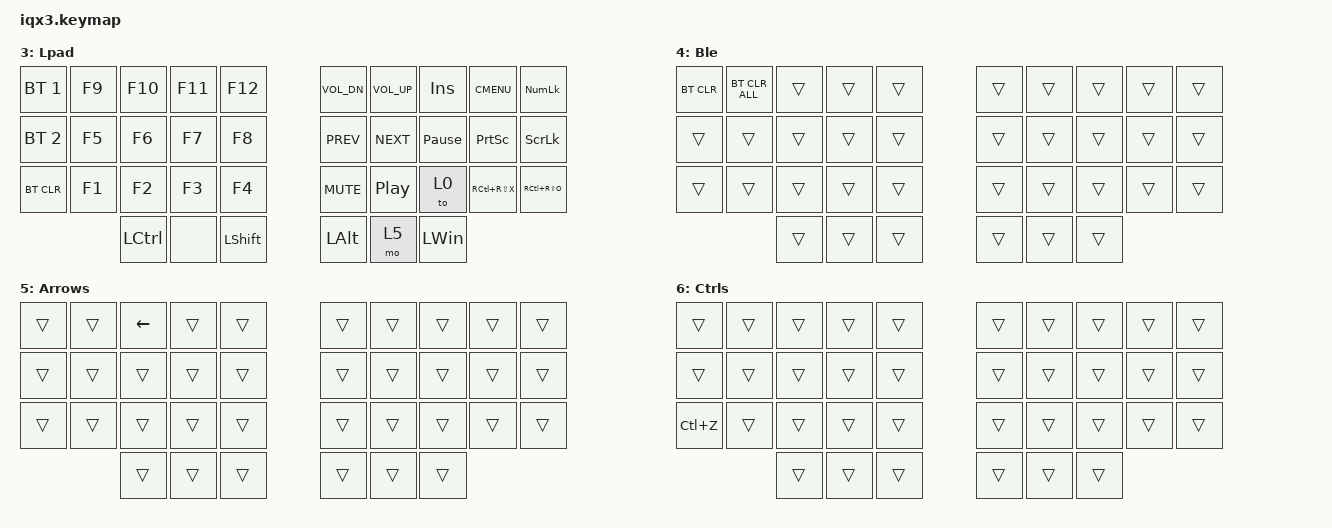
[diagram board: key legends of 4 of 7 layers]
/*
 * Copyright (c) 2020 The ZMK Contributors
 *
 * SPDX-License-Identifier: MIT
 */

#include <behaviors.dtsi>
#include <dt-bindings/zmk/bt.h>
#include <dt-bindings/zmk/keys.h>

/ {
    keymap0: keymap {
        compatible = "zmk,keymap";

        Base {
            // &mt LCTRL ESC  &lt 1 SPACE  &kp LSHFT  &mt LALT TAB  &lt 2 SPACE  &mt LWIN DEL

            // | --- |   Q   |   W   |   E   |   R   |   T   |   Y   |   U   |   I   |   O   |   P   |  --- |
            // | --- |   A   |   S   |   D   |   F   |   G   |   H   |   J   |   K   |   L   |  Ent  |  --- |
            // | --- |   Z   |   X   |   C   |   V   |   B   |   N   |   M   | 3,Spc |  Del  |  BS   |  --- |
            // | --- |  ---  |  ---  | LCtrl | MO(1) | LSht  |  LAlt | MO(2) | LWin  |  ---  |  ---  |  --- | 
            bindings = <
&none    &lt 1 Q     &kp W     &kp E         &kp R       &kp T     &kp Y        &kp U       &kp I          &kp O       &kp P     &none
&none    &lt 2 A     &kp S     &kp D         &kp F       &kp G     &kp H        &kp J       &kp K          &kp L       &kp ENTER &none 
&none    &lt 3 Z     &kp X     &kp C         &kp V       &kp B     &kp N        &kp M       &kp COMMA    &kp DOT   &kp BSPC  &none
&none    &none     &none     &kp ESC       &kp TAB     &kp CAPS  &kp LSHFT    &kp LCTRL   &kp SPACE   &none       &none     &none        
            >;
        };

        Number {
            // | ---| a 1 2 3 + - * / = bspc --- |
            // | --- 0 4 5 6 ! @ # $ % ^--- |
            // | --- . 7 8 9 & * () _ |  --- |
            // | --- 
            // | --- |   7   |   8   |   9   |   .   |   +   |   *   |   $   |   :   |   |   |   `   |  --- |
            // | --- |   4   |   5   |   6   |   0   |   -   |   /   |   #   |   {   |   }   |   ;   |  --- |
            // | --- |   1   |   2   |   3   |  BS   | P-Ent |  CAPS | #Spc  |   ,   |   .   | !#BS  |  --- |
            // | --- |  ---  |  ---  | LCtrl | TO(0) | LSht  |  LAlt | #Spc  | LWin  |  ---  |  ---  |  --- | 
            bindings = <
 &none   &kp N7    &kp N8    &kp N9    &kp KP_DOT &kp KP_PLUS         &kp KP_MULTIPLY  &kp DLLR      &kp COLON  &kp PIPE   &kp GRAVE    &none 
 &none   &kp N4    &kp N5    &kp N6    &kp N0     &kp KP_MINUS        &kp KP_SLASH     &kp HASH      &kp LBRC   &kp RBRC   &kp SEMI     &none  
 &none   &kp N1    &kp N2    &kp N3    &kp BSPC   &kp EQUAL           &kp BSLH         &kp AMPS      &kp LT     &kp GT     &kp SQT      &none
 &none   &none     &none     &kp LCTRL &to 0      &mt LSHFT KP_ENTER  &kp LALT         &kp LG(SPACE) &kp LWIN   &none      &none        &none
            >;
        };

        Icons {
            // | --- |   ~   |   %   |   _   |   ^   |   <   |   >   |  Home |   Up  |  End  | PgUp  |  --- |
            // | --- |   @   |   "   |   !   |   ?   |   (   |   )   |  Left |   Dn  | Right | PgDn  |  --- |
            // | --- |   [   |   ]   |   '   |   &   |   =   |   /   | ^!+/  |  Esc  |  Tab  | !#Del |  --- |
            // | --- |  ---  |  ---  | LCtrl | #Spc  | LSht  |  LAlt | TO(0) | LWin  |  ---  |  ---  |  --- | 

            bindings = <
  &kp TILDE  &kp PRCNT  &kp UNDER  &kp CARET  &kp PLUS   &kp STAR   &kp HOME               &kp UP    &kp END    &kp PG_UP
  &kp AT     &kp DQT    &kp EXCL   &kp QMARK  &kp MINUS  &kp SLASH  &kp LEFT               &kp DOWN  &kp RIGHT  &kp PG_DN
  &kp LBKT   &kp RBKT   &kp LPAR   &kp RPAR   &kp EQUAL  &kp BSLH   &kp LS(LC(LA(SLASH)))  &kp ESC   &kp TAB    &kp DEL
                        &kp LCTRL  &kp CAPS   &kp LSHFT  &kp LALT   &to 0                  &kp LWIN
            >;
        };

        Lpad {
            // | --- |  BT1  |   F9  |  F10  |  F11  |  F12  |  ^!+- |  ^!+= | VolUp |S-lock | N-lock|  --- |
            // | --- |  BT2  |   F5  |   F6  |   F7  |   F8  |  Prev |  Next | VolDn | Menu  | Insert|  --- |
            // | --- | BT-clr|   F1  |   F2  |   F3  |   F4  |  Mute |  Play | TO(0) |   ^   |  BL   |  --- |
            // | --- |  ---  |  ---  | LCtrl |  !+[  | LSht  |  LAlt |  !+]  | LWin  |  ---  |  ---  |  --- | 

            bindings = <
  &bt BT_SEL 1  &kp F9  &kp F10    &kp F11  &kp F12    &kp C_VOL_DN  &kp C_VOL_UP  &kp INS          &kp K_CMENU    &kp KP_NLCK
  &bt BT_SEL 2  &kp F5  &kp F6     &kp F7   &kp F8     &kp C_PREV    &kp C_NEXT    &kp PAUSE_BREAK  &kp PSCRN      &kp SLCK
  &bt BT_CLR    &kp F1  &kp F2     &kp F3   &kp F4     &kp C_MUTE    &kp C_PP      &to 0            &kp RC(RS(X))  &kp RC(RS(O))
                        &kp LCTRL  &none    &kp LSHFT  &kp LALT      &mo 5         &kp LWIN
            >;
        };

        Ble {
            bindings = <
  &bt BT_CLR  &bt BT_CLR_ALL  &trans  &trans  &trans  &trans  &trans  &trans  &trans  &trans
  &trans      &trans          &trans  &trans  &trans  &trans  &trans  &trans  &trans  &trans
  &trans      &trans          &trans  &trans  &trans  &trans  &trans  &trans  &trans  &trans
                              &trans  &trans  &trans  &trans  &trans  &trans
            >;
        };

        Arrows {
            bindings = <
  &trans  &trans  &kp LEFT  &trans  &trans  &trans  &trans  &trans  &trans  &trans
  &trans  &trans  &trans    &trans  &trans  &trans  &trans  &trans  &trans  &trans
  &trans  &trans  &trans    &trans  &trans  &trans  &trans  &trans  &trans  &trans
                  &trans    &trans  &trans  &trans  &trans  &trans
            >;
        };

        Ctrls {
            bindings = <
  &trans     &trans  &trans  &trans  &trans  &trans  &trans  &trans  &trans  &trans
  &trans     &trans  &trans  &trans  &trans  &trans  &trans  &trans  &trans  &trans
  &kp LC(Z)  &trans  &trans  &trans  &trans  &trans  &trans  &trans  &trans  &trans
                     &trans  &trans  &trans  &trans  &trans  &trans
            >;
        };
    };
};
